VERSION ""

NS_ :

BS_:

BU_:

BO_ 3221225472 VECTOR__INDEPENDENT_SIG_MSG: 0 Vector__XXX
 SG_ NewSignal_0004 : 24|8@1+ (1,0) [0|0] "" Vector__XXX
 SG_ NewSignal_0005 : 48|16@1+ (1,0) [0|0] "" Vector__XXX
 SG_ NewSignal_0001 : 0|8@1+ (1,0) [0|0] "" Vector__XXX
 SG_ NewSignal_0002 : 8|8@1+ (1,0) [0|0] "" Vector__XXX

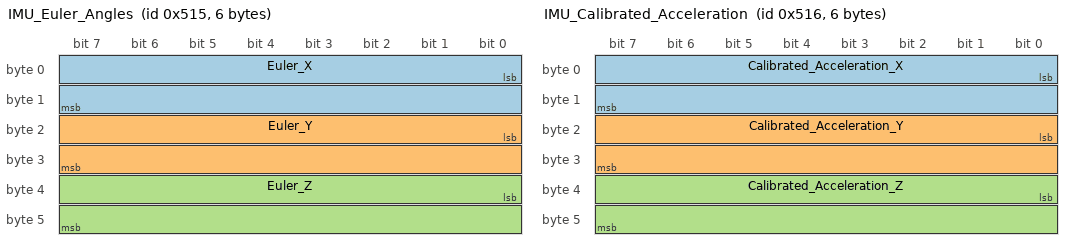
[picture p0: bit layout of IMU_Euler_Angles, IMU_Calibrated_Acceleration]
BO_ 1301 IMU_Euler_Angles: 6 Vector__XXX
 SG_ Euler_X : 0|16@1+ (0.01,0) [-180|180] "°" Vector__XXX
 SG_ Euler_Y : 16|16@1+ (0.01,0) [-90|90] "°" Vector__XXX
 SG_ Euler_Z : 32|16@1+ (0.01,0) [-180|180] "°" Vector__XXX

BO_ 1302 IMU_Calibrated_Acceleration: 6 Vector__XXX
 SG_ Calibrated_Acceleration_X : 0|16@1+ (0.001,-65.53) [0|0] "" Vector__XXX
 SG_ Calibrated_Acceleration_Y : 16|16@1+ (1.526e-05,-0.007) [0|0] "" Vector__XXX
 SG_ Calibrated_Acceleration_Z : 32|16@1+ (0.001,-65.529) [0|0] "" Vector__XXX

BO_ 1304 IMU_Temperature: 6 Vector__XXX
 SG_ Temperature : 0|16@1+ (1,0) [0|0] "°C" Vector__XXX

BO_ 1305 UltraSonic_Voltage: 8 Vector__XXX
 SG_ FrontUltrasonic : 0|16@1+ (1,0) [0|0] "V" Vector__XXX
 SG_ RearUltrasonic : 16|16@1+ (1,0) [0|0] "V" Vector__XXX

BO_ 1306 Water_Sensor_V_H: 8 Vector__XXX
 SG_ Water_Sensor_1 : 0|1@1+ (1,0) [0|0] "V" Vector__XXX
 SG_ Water_Sensor_2 : 1|1@1+ (1,0) [0|0] "V" Vector__XXX

BO_ 1307 Gearbox_Temps: 8 Vector__XXX
 SG_ Gearbox1 : 0|16@1+ (1,0) [0|0] "°C" Vector__XXX
 SG_ Gearbox2 : 16|16@1+ (1,0) [0|0] "°C" Vector__XXX

BA_DEF_  "BusType" STRING ;
BA_DEF_DEF_  "BusType" "CAN";
